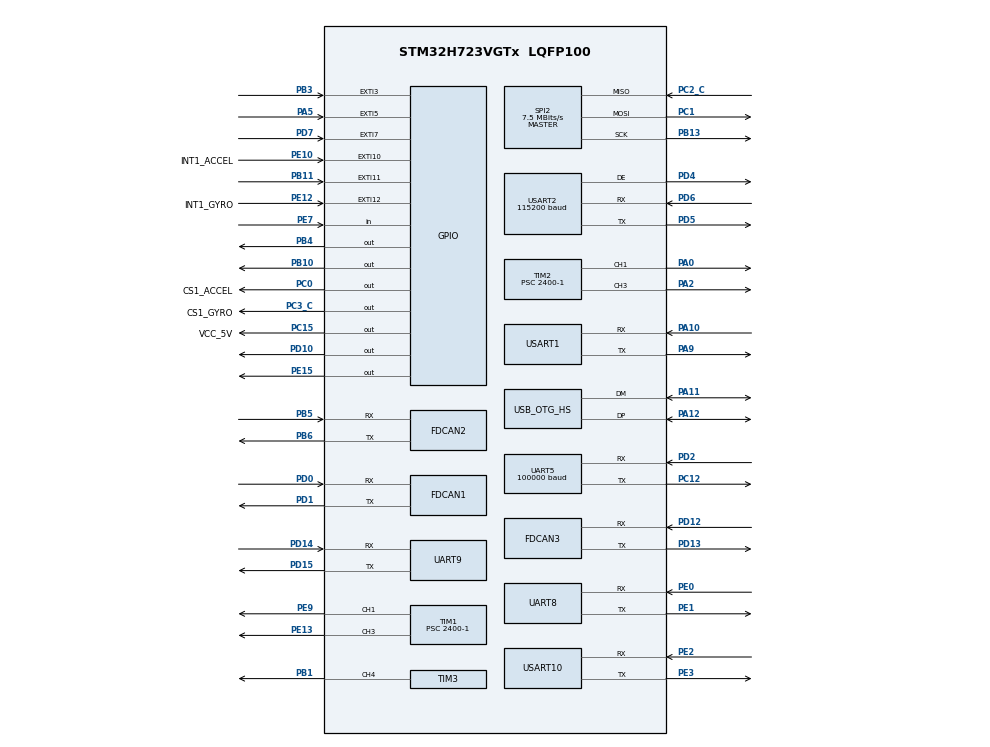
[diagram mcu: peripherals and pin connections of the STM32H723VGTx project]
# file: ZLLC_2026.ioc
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CORTEX_M7.CPU_DCache=Disabled
CORTEX_M7.CPU_ICache=Disabled
CORTEX_M7.MPU_Control=__NULL
CORTEX_M7.default_mode_Activation=0
Dma.Request0=UART5_RX
Dma.Request1=SPI2_RX
Dma.Request10=USART2_TX
Dma.Request2=SPI2_TX
Dma.Request3=USART10_RX
Dma.Request4=USART1_RX
Dma.Request5=UART8_RX
Dma.Request6=UART8_TX
Dma.Request7=UART9_RX
Dma.Request8=UART9_TX
Dma.Request9=USART2_RX
Dma.SPI2_RX.1.Direction=DMA_PERIPH_TO_MEMORY
Dma.SPI2_RX.1.EventEnable=DISABLE
Dma.SPI2_RX.1.FIFOMode=DMA_FIFOMODE_DISABLE
Dma.SPI2_RX.1.Instance=DMA1_Stream2
Dma.SPI2_RX.1.MemDataAlignment=DMA_MDATAALIGN_BYTE
Dma.SPI2_RX.1.MemInc=DMA_MINC_ENABLE
Dma.SPI2_RX.1.Mode=DMA_NORMAL
Dma.SPI2_RX.1.PeriphDataAlignment=DMA_PDATAALIGN_BYTE
Dma.SPI2_RX.1.PeriphInc=DMA_PINC_DISABLE
Dma.SPI2_RX.1.Polarity=HAL_DMAMUX_REQ_GEN_RISING
Dma.SPI2_RX.1.Priority=DMA_PRIORITY_VERY_HIGH
Dma.SPI2_RX.1.RequestNumber=1
Dma.SPI2_RX.1.SignalID=NONE
Dma.SPI2_RX.1.SyncEnable=DISABLE
Dma.SPI2_RX.1.SyncPolarity=HAL_DMAMUX_SYNC_NO_EVENT
Dma.SPI2_RX.1.SyncRequestNumber=1
Dma.SPI2_RX.1.SyncSignalID=NONE
Dma.SPI2_TX.2.Direction=DMA_MEMORY_TO_PERIPH
Dma.SPI2_TX.2.EventEnable=DISABLE
Dma.SPI2_TX.2.FIFOMode=DMA_FIFOMODE_DISABLE
Dma.SPI2_TX.2.Instance=DMA1_Stream1
Dma.SPI2_TX.2.MemDataAlignment=DMA_MDATAALIGN_BYTE
Dma.SPI2_TX.2.MemInc=DMA_MINC_ENABLE
Dma.SPI2_TX.2.Mode=DMA_NORMAL
Dma.SPI2_TX.2.PeriphDataAlignment=DMA_PDATAALIGN_BYTE
Dma.SPI2_TX.2.PeriphInc=DMA_PINC_DISABLE
Dma.SPI2_TX.2.Polarity=HAL_DMAMUX_REQ_GEN_RISING
Dma.SPI2_TX.2.Priority=DMA_PRIORITY_HIGH
Dma.SPI2_TX.2.RequestNumber=1
Dma.SPI2_TX.2.SignalID=NONE
Dma.SPI2_TX.2.SyncEnable=DISABLE
Dma.SPI2_TX.2.SyncPolarity=HAL_DMAMUX_SYNC_NO_EVENT
Dma.SPI2_TX.2.SyncRequestNumber=1
Dma.SPI2_TX.2.SyncSignalID=NONE
Dma.UART5_RX.0.Direction=DMA_PERIPH_TO_MEMORY
Dma.UART5_RX.0.EventEnable=DISABLE
Dma.UART5_RX.0.FIFOMode=DMA_FIFOMODE_DISABLE
Dma.UART5_RX.0.Instance=DMA1_Stream0
Dma.UART5_RX.0.MemDataAlignment=DMA_MDATAALIGN_BYTE
Dma.UART5_RX.0.MemInc=DMA_MINC_ENABLE
Dma.UART5_RX.0.Mode=DMA_NORMAL
Dma.UART5_RX.0.PeriphDataAlignment=DMA_PDATAALIGN_BYTE
Dma.UART5_RX.0.PeriphInc=DMA_PINC_DISABLE
Dma.UART5_RX.0.Polarity=HAL_DMAMUX_REQ_GEN_RISING
Dma.UART5_RX.0.Priority=DMA_PRIORITY_VERY_HIGH
Dma.UART5_RX.0.RequestNumber=1
Dma.UART5_RX.0.SignalID=NONE
Dma.UART5_RX.0.SyncEnable=DISABLE
Dma.UART5_RX.0.SyncPolarity=HAL_DMAMUX_SYNC_NO_EVENT
Dma.UART5_RX.0.SyncRequestNumber=1
Dma.UART5_RX.0.SyncSignalID=NONE
Dma.UART8_RX.5.Direction=DMA_PERIPH_TO_MEMORY
Dma.UART8_RX.5.EventEnable=DISABLE
Dma.UART8_RX.5.FIFOMode=DMA_FIFOMODE_DISABLE
Dma.UART8_RX.5.Instance=DMA1_Stream6
Dma.UART8_RX.5.MemDataAlignment=DMA_MDATAALIGN_BYTE
Dma.UART8_RX.5.MemInc=DMA_MINC_ENABLE
Dma.UART8_RX.5.Mode=DMA_CIRCULAR
Dma.UART8_RX.5.PeriphDataAlignment=DMA_PDATAALIGN_BYTE
Dma.UART8_RX.5.PeriphInc=DMA_PINC_DISABLE
Dma.UART8_RX.5.Polarity=HAL_DMAMUX_REQ_GEN_RISING
Dma.UART8_RX.5.Priority=DMA_PRIORITY_LOW
Dma.UART8_RX.5.RequestNumber=1
Dma.UART8_RX.5.SignalID=NONE
Dma.UART8_RX.5.SyncEnable=DISABLE
Dma.UART8_RX.5.SyncPolarity=HAL_DMAMUX_SYNC_NO_EVENT
Dma.UART8_RX.5.SyncRequestNumber=1
Dma.UART8_RX.5.SyncSignalID=NONE
Dma.UART8_TX.6.Direction=DMA_MEMORY_TO_PERIPH
Dma.UART8_TX.6.EventEnable=DISABLE
Dma.UART8_TX.6.FIFOMode=DMA_FIFOMODE_DISABLE
Dma.UART8_TX.6.Instance=DMA1_Stream7
Dma.UART8_TX.6.MemDataAlignment=DMA_MDATAALIGN_BYTE
Dma.UART8_TX.6.MemInc=DMA_MINC_ENABLE
Dma.UART8_TX.6.Mode=DMA_NORMAL
Dma.UART8_TX.6.PeriphDataAlignment=DMA_PDATAALIGN_BYTE
Dma.UART8_TX.6.PeriphInc=DMA_PINC_DISABLE
Dma.UART8_TX.6.Polarity=HAL_DMAMUX_REQ_GEN_RISING
Dma.UART8_TX.6.Priority=DMA_PRIORITY_LOW
Dma.UART8_TX.6.RequestNumber=1
Dma.UART8_TX.6.SignalID=NONE
Dma.UART8_TX.6.SyncEnable=DISABLE
Dma.UART8_TX.6.SyncPolarity=HAL_DMAMUX_SYNC_NO_EVENT
Dma.UART8_TX.6.SyncRequestNumber=1
Dma.UART8_TX.6.SyncSignalID=NONE
Dma.UART9_RX.7.Direction=DMA_PERIPH_TO_MEMORY
Dma.UART9_RX.7.EventEnable=DISABLE
Dma.UART9_RX.7.FIFOMode=DMA_FIFOMODE_DISABLE
Dma.UART9_RX.7.Instance=DMA2_Stream0
Dma.UART9_RX.7.MemDataAlignment=DMA_MDATAALIGN_BYTE
Dma.UART9_RX.7.MemInc=DMA_MINC_ENABLE
Dma.UART9_RX.7.Mode=DMA_CIRCULAR
Dma.UART9_RX.7.PeriphDataAlignment=DMA_PDATAALIGN_BYTE
Dma.UART9_RX.7.PeriphInc=DMA_PINC_DISABLE
Dma.UART9_RX.7.Polarity=HAL_DMAMUX_REQ_GEN_RISING
Dma.UART9_RX.7.Priority=DMA_PRIORITY_LOW
Dma.UART9_RX.7.RequestNumber=1
Dma.UART9_RX.7.SignalID=NONE
Dma.UART9_RX.7.SyncEnable=DISABLE
Dma.UART9_RX.7.SyncPolarity=HAL_DMAMUX_SYNC_NO_EVENT
Dma.UART9_RX.7.SyncRequestNumber=1
Dma.UART9_RX.7.SyncSignalID=NONE
Dma.UART9_TX.8.Direction=DMA_MEMORY_TO_PERIPH
Dma.UART9_TX.8.EventEnable=DISABLE
Dma.UART9_TX.8.FIFOMode=DMA_FIFOMODE_DISABLE
Dma.UART9_TX.8.Instance=DMA2_Stream1
Dma.UART9_TX.8.MemDataAlignment=DMA_MDATAALIGN_BYTE
Dma.UART9_TX.8.MemInc=DMA_MINC_ENABLE
Dma.UART9_TX.8.Mode=DMA_NORMAL
Dma.UART9_TX.8.PeriphDataAlignment=DMA_PDATAALIGN_BYTE
Dma.UART9_TX.8.PeriphInc=DMA_PINC_DISABLE
Dma.UART9_TX.8.Polarity=HAL_DMAMUX_REQ_GEN_RISING
Dma.UART9_TX.8.Priority=DMA_PRIORITY_LOW
Dma.UART9_TX.8.RequestNumber=1
Dma.UART9_TX.8.SignalID=NONE
Dma.UART9_TX.8.SyncEnable=DISABLE
Dma.UART9_TX.8.SyncPolarity=HAL_DMAMUX_SYNC_NO_EVENT
Dma.UART9_TX.8.SyncRequestNumber=1
Dma.UART9_TX.8.SyncSignalID=NONE
Dma.USART10_RX.3.Direction=DMA_PERIPH_TO_MEMORY
Dma.USART10_RX.3.EventEnable=DISABLE
Dma.USART10_RX.3.FIFOMode=DMA_FIFOMODE_ENABLE
Dma.USART10_RX.3.FIFOThreshold=DMA_FIFO_THRESHOLD_FULL
Dma.USART10_RX.3.Instance=DMA1_Stream3
Dma.USART10_RX.3.MemBurst=DMA_MBURST_SINGLE
Dma.USART10_RX.3.MemDataAlignment=DMA_MDATAALIGN_BYTE
Dma.USART10_RX.3.MemInc=DMA_MINC_ENABLE
Dma.USART10_RX.3.Mode=DMA_CIRCULAR
Dma.USART10_RX.3.PeriphBurst=DMA_PBURST_SINGLE
Dma.USART10_RX.3.PeriphDataAlignment=DMA_PDATAALIGN_BYTE
Dma.USART10_RX.3.PeriphInc=DMA_PINC_DISABLE
Dma.USART10_RX.3.Polarity=HAL_DMAMUX_REQ_GEN_RISING
Dma.USART10_RX.3.Priority=DMA_PRIORITY_LOW
Dma.USART10_RX.3.RequestNumber=1
Dma.USART10_RX.3.SignalID=NONE
Dma.USART10_RX.3.SyncEnable=DISABLE
Dma.USART10_RX.3.SyncPolarity=HAL_DMAMUX_SYNC_NO_EVENT
Dma.USART10_RX.3.SyncRequestNumber=1
Dma.USART10_RX.3.SyncSignalID=NONE
Dma.USART1_RX.4.Direction=DMA_PERIPH_TO_MEMORY
Dma.USART1_RX.4.EventEnable=DISABLE
Dma.USART1_RX.4.FIFOMode=DMA_FIFOMODE_DISABLE
Dma.USART1_RX.4.Instance=DMA1_Stream4
Dma.USART1_RX.4.MemDataAlignment=DMA_MDATAALIGN_BYTE
Dma.USART1_RX.4.MemInc=DMA_MINC_ENABLE
Dma.USART1_RX.4.Mode=DMA_CIRCULAR
Dma.USART1_RX.4.PeriphDataAlignment=DMA_PDATAALIGN_BYTE
Dma.USART1_RX.4.PeriphInc=DMA_PINC_DISABLE
Dma.USART1_RX.4.Polarity=HAL_DMAMUX_REQ_GEN_RISING
Dma.USART1_RX.4.Priority=DMA_PRIORITY_LOW
Dma.USART1_RX.4.RequestNumber=1
Dma.USART1_RX.4.SignalID=NONE
Dma.USART1_RX.4.SyncEnable=DISABLE
Dma.USART1_RX.4.SyncPolarity=HAL_DMAMUX_SYNC_NO_EVENT
Dma.USART1_RX.4.SyncRequestNumber=1
Dma.USART1_RX.4.SyncSignalID=NONE
Dma.USART2_RX.9.Direction=DMA_PERIPH_TO_MEMORY
Dma.USART2_RX.9.EventEnable=DISABLE
Dma.USART2_RX.9.FIFOMode=DMA_FIFOMODE_DISABLE
Dma.USART2_RX.9.Instance=DMA2_Stream2
Dma.USART2_RX.9.MemDataAlignment=DMA_MDATAALIGN_BYTE
Dma.USART2_RX.9.MemInc=DMA_MINC_ENABLE
Dma.USART2_RX.9.Mode=DMA_CIRCULAR
Dma.USART2_RX.9.PeriphDataAlignment=DMA_PDATAALIGN_BYTE
Dma.USART2_RX.9.PeriphInc=DMA_PINC_DISABLE
Dma.USART2_RX.9.Polarity=HAL_DMAMUX_REQ_GEN_RISING
Dma.USART2_RX.9.Priority=DMA_PRIORITY_MEDIUM
Dma.USART2_RX.9.RequestNumber=1
Dma.USART2_RX.9.SignalID=NONE
Dma.USART2_RX.9.SyncEnable=DISABLE
Dma.USART2_RX.9.SyncPolarity=HAL_DMAMUX_SYNC_NO_EVENT
Dma.USART2_RX.9.SyncRequestNumber=1
Dma.USART2_RX.9.SyncSignalID=NONE
Dma.USART2_TX.10.Direction=DMA_MEMORY_TO_PERIPH
Dma.USART2_TX.10.EventEnable=DISABLE
Dma.USART2_TX.10.FIFOMode=DMA_FIFOMODE_DISABLE
Dma.USART2_TX.10.Instance=DMA2_Stream3
Dma.USART2_TX.10.MemDataAlignment=DMA_MDATAALIGN_BYTE
Dma.USART2_TX.10.MemInc=DMA_MINC_ENABLE
Dma.USART2_TX.10.Mode=DMA_NORMAL
Dma.USART2_TX.10.PeriphDataAlignment=DMA_PDATAALIGN_BYTE
Dma.USART2_TX.10.PeriphInc=DMA_PINC_DISABLE
Dma.USART2_TX.10.Polarity=HAL_DMAMUX_REQ_GEN_RISING
Dma.USART2_TX.10.Priority=DMA_PRIORITY_MEDIUM
Dma.USART2_TX.10.RequestNumber=1
Dma.USART2_TX.10.SignalID=NONE
Dma.USART2_TX.10.SyncEnable=DISABLE
Dma.USART2_TX.10.SyncPolarity=HAL_DMAMUX_SYNC_NO_EVENT
Dma.USART2_TX.10.SyncRequestNumber=1
Dma.USART2_TX.10.SyncSignalID=NONE
FDCAN1.AutoRetransmission=DISABLE
FDCAN1.CalculateBaudRateNominal=1000000
FDCAN1.CalculateTimeBitNominal=1000
FDCAN1.CalculateTimeQuantumNominal=25.0
FDCAN1.DataPrescaler=3
FDCAN1.DataSyncJumpWidth=10
FDCAN1.DataTimeSeg1=29
FDCAN1.DataTimeSeg2=10
FDCAN1.ExtFiltersNbr=0
FDCAN1.MessageRAMOffset=0
FDCAN1.NominalPrescaler=3
FDCAN1.NominalSyncJumpWidth=10
FDCAN1.NominalTimeSeg1=29
FDCAN1.NominalTimeSeg2=10
FDCAN1.ProtocolException=ENABLE
FDCAN1.RxBuffersNbr=0
FDCAN1.RxFifo0ElmtSize=FDCAN_DATA_BYTES_8
FDCAN1.RxFifo0ElmtsNbr=12
FDCAN1.RxFifo1ElmtSize=FDCAN_DATA_BYTES_8
FDCAN1.StdFiltersNbr=1
FDCAN1.TxBuffersNbr=0
FDCAN1.TxEventsNbr=0
FDCAN1.TxFifoQueueElmtsNbr=12
FDCAN2.CalculateBaudRateNominal=1000000
FDCAN2.CalculateTimeBitNominal=1000
FDCAN2.CalculateTimeQuantumNominal=25.0
FDCAN2.DataPrescaler=3
FDCAN2.DataSyncJumpWidth=10
FDCAN2.DataTimeSeg1=29
FDCAN2.DataTimeSeg2=10
FDCAN2.ExtFiltersNbr=0
FDCAN2.MessageRAMOffset=854
FDCAN2.NominalPrescaler=3
FDCAN2.NominalSyncJumpWidth=10
FDCAN2.NominalTimeSeg1=29
FDCAN2.NominalTimeSeg2=10
FDCAN2.ProtocolException=ENABLE
FDCAN2.RxFifo0ElmtsNbr=0
FDCAN2.RxFifo1ElmtsNbr=12
FDCAN2.StdFiltersNbr=1
FDCAN2.TxFifoQueueElmtsNbr=12
FDCAN3.CalculateBaudRateNominal=1000000
FDCAN3.CalculateTimeBitNominal=1000
FDCAN3.CalculateTimeQuantumNominal=25.0
FDCAN3.DataPrescaler=3
FDCAN3.DataSyncJumpWidth=10
FDCAN3.DataTimeSeg1=29
FDCAN3.DataTimeSeg2=10
FDCAN3.ExtFiltersNbr=0
FDCAN3.MessageRAMOffset=1707
FDCAN3.NominalPrescaler=3
FDCAN3.NominalSyncJumpWidth=10
FDCAN3.NominalTimeSeg1=29
FDCAN3.NominalTimeSeg2=10
FDCAN3.ProtocolException=ENABLE
FDCAN3.RxFifo0ElmtsNbr=12
FDCAN3.RxFifo1ElmtsNbr=0
FDCAN3.StdFiltersNbr=1
FDCAN3.TxFifoQueueElmtsNbr=12
IWDG1.Prescaler=IWDG_PRESCALER_64
IWDG1.Reload=125
Mcu.Family=STM32H7
Mcu.Name=STM32H723VGTx
Mcu.Package=LQFP100
NVIC.DMA1_Stream0_IRQn=true\:0\:0\:true\:false\:true\:false\:true\:true
NVIC.DMA1_Stream1_IRQn=true\:0\:0\:true\:false\:true\:false\:true\:true
NVIC.DMA1_Stream2_IRQn=true\:0\:0\:true\:false\:true\:false\:true\:true
NVIC.DMA1_Stream3_IRQn=true\:0\:0\:true\:false\:true\:false\:true\:true
NVIC.DMA1_Stream4_IRQn=true\:1\:0\:true\:false\:true\:false\:true\:true
NVIC.DMA1_Stream6_IRQn=true\:0\:0\:false\:false\:true\:false\:true\:true
NVIC.DMA1_Stream7_IRQn=true\:0\:0\:false\:false\:true\:false\:true\:true
NVIC.DMA2_Stream0_IRQn=true\:0\:0\:false\:false\:true\:false\:true\:true
NVIC.DMA2_Stream1_IRQn=true\:0\:0\:false\:false\:true\:false\:true\:true
NVIC.DMA2_Stream2_IRQn=true\:0\:0\:false\:false\:true\:false\:true\:true
NVIC.DMA2_Stream3_IRQn=true\:0\:0\:false\:false\:true\:false\:true\:true
NVIC.EXTI15_10_IRQn=true\:0\:0\:true\:false\:true\:true\:true\:true
NVIC.EXTI3_IRQn=true\:0\:0\:false\:false\:true\:true\:true\:true
NVIC.EXTI9_5_IRQn=true\:0\:0\:false\:false\:true\:true\:true\:true
NVIC.FDCAN1_IT0_IRQn=true\:1\:0\:true\:false\:true\:true\:true\:true
NVIC.FDCAN2_IT0_IRQn=true\:1\:0\:true\:false\:true\:true\:true\:true
NVIC.FDCAN2_IT1_IRQn=true\:0\:0\:false\:false\:true\:true\:true\:true
NVIC.FDCAN3_IT0_IRQn=true\:3\:0\:true\:false\:true\:true\:true\:true
NVIC.OTG_HS_IRQn=true\:0\:0\:true\:false\:true\:true\:true\:true
NVIC.PriorityGroup=NVIC_PRIORITYGROUP_3
NVIC.SPI2_IRQn=true\:0\:0\:true\:false\:true\:true\:true\:true
NVIC.TIM5_IRQn=true\:1\:0\:true\:false\:true\:true\:true\:true
NVIC.UART5_IRQn=true\:6\:0\:true\:false\:true\:true\:true\:true
NVIC.UART8_IRQn=true\:6\:0\:true\:false\:true\:true\:true\:true
NVIC.UART9_IRQn=true\:6\:0\:true\:false\:true\:true\:true\:true
NVIC.USART10_IRQn=true\:6\:0\:true\:false\:true\:true\:true\:true
NVIC.USART1_IRQn=true\:1\:0\:true\:false\:true\:true\:true\:true
NVIC.USART2_IRQn=true\:3\:0\:true\:false\:true\:true\:true\:true
PA0.Signal=S_TIM2_CH1_ETR
PA10.Mode=Asynchronous
PA10.Signal=USART1_RX
PA11.Mode=Device_Only_FS
PA11.Signal=USB_OTG_HS_DM
PA12.Mode=Device_Only_FS
PA12.Signal=USB_OTG_HS_DP
PA13(JTMS/SWDIO).Mode=Serial_Wire
PA13(JTMS/SWDIO).Signal=DEBUG_JTMS-SWDIO
PA14(JTCK/SWCLK).Mode=Serial_Wire
PA14(JTCK/SWCLK).Signal=DEBUG_JTCK-SWCLK
PA2.Signal=S_TIM2_CH3
PA5.GPIO_PuPd=GPIO_PULLDOWN
PA5.Signal=GPXTI5
PA9.Mode=Asynchronous
PA9.Signal=USART1_TX
PB1.Signal=S_TIM3_CH4
PB10.GPIO_PuPd=GPIO_PULLUP
PB10.PinState=GPIO_PIN_SET
PB10.Signal=GPIO_Output
PB11.GPIO_PuPd=GPIO_PULLDOWN
PB11.Signal=GPXTI11
PB13.GPIO_Speed=GPIO_SPEED_FREQ_VERY_HIGH
PB13.Mode=Full_Duplex_Master
PB13.Signal=SPI2_SCK
PB3(JTDO/TRACESWO).GPIO_ModeDefaultEXTI=GPIO_MODE_IT_RISING
PB3(JTDO/TRACESWO).GPIO_PuPd=GPIO_PULLDOWN
PB3(JTDO/TRACESWO).Signal=GPXTI3
PB4(NJTRST).GPIO_PuPd=GPIO_PULLUP
PB4(NJTRST).PinState=GPIO_PIN_SET
PB4(NJTRST).Signal=GPIO_Output
PB5.Mode=FDCAN_Activate
PB5.Signal=FDCAN2_RX
PB6.Mode=FDCAN_Activate
PB6.Signal=FDCAN2_TX
PC0.GPIO_Label=CS1_ACCEL
PC0.GPIO_PuPd=GPIO_PULLUP
PC0.GPIO_Speed=GPIO_SPEED_FREQ_HIGH
PC0.PinState=GPIO_PIN_SET
PC0.Signal=GPIO_Output
PC1.GPIO_Speed=GPIO_SPEED_FREQ_VERY_HIGH
PC1.Mode=Full_Duplex_Master
PC1.Signal=SPI2_MOSI
PC12.Mode=Asynchronous
PC12.Signal=UART5_TX
PC15-OSC32_OUT.GPIO_Label=VCC_5V
PC15-OSC32_OUT.PinState=GPIO_PIN_SET
PC15-OSC32_OUT.Signal=GPIO_Output
PC2_C.GPIO_Speed=GPIO_SPEED_FREQ_VERY_HIGH
PC2_C.Mode=Full_Duplex_Master
PC2_C.Signal=SPI2_MISO
PC3_C.GPIO_Label=CS1_GYRO
PC3_C.GPIO_PuPd=GPIO_PULLUP
PC3_C.GPIO_Speed=GPIO_SPEED_FREQ_HIGH
PC3_C.PinState=GPIO_PIN_SET
PC3_C.Signal=GPIO_Output
PD0.Mode=FDCAN_Activate
PD0.Signal=FDCAN1_RX
PD1.Mode=FDCAN_Activate
PD1.Signal=FDCAN1_TX
PD10.GPIO_PuPd=GPIO_PULLUP
PD10.PinState=GPIO_PIN_SET
PD10.Signal=GPIO_Output
PD12.Mode=FDCAN_Activate
PD12.Signal=FDCAN3_RX
PD13.Mode=FDCAN_Activate
PD13.Signal=FDCAN3_TX
PD14.Mode=Asynchronous
PD14.Signal=UART9_RX
PD15.Mode=Asynchronous
PD15.Signal=UART9_TX
PD2.Mode=Asynchronous
PD2.Signal=UART5_RX
PD4.Mode=Hardware Flow Control (RS485)
PD4.Signal=USART2_DE
PD5.Mode=Asynchronous
PD5.Signal=USART2_TX
PD6.Mode=Asynchronous
PD6.Signal=USART2_RX
PD7.GPIO_PuPd=GPIO_PULLDOWN
PD7.Signal=GPXTI7
PE0.Mode=Asynchronous
PE0.Signal=UART8_RX
PE1.Mode=Asynchronous
PE1.Signal=UART8_TX
PE10.GPIO_Label=INT1_ACCEL
PE10.GPIO_ModeDefaultEXTI=GPIO_MODE_IT_FALLING
PE10.GPIO_PuPd=GPIO_PULLUP
PE10.Signal=GPXTI10
PE12.GPIO_Label=INT1_GYRO
PE12.GPIO_ModeDefaultEXTI=GPIO_MODE_IT_FALLING
PE12.GPIO_PuPd=GPIO_PULLUP
PE12.Signal=GPXTI12
PE13.Signal=S_TIM1_CH3
PE15.GPIO_PuPd=GPIO_PULLUP
PE15.PinState=GPIO_PIN_SET
PE15.Signal=GPIO_Output
PE2.Mode=Asynchronous
PE2.Signal=USART10_RX
PE3.Mode=Asynchronous
PE3.Signal=USART10_TX
PE7.GPIO_PuPd=GPIO_PULLUP
PE7.Signal=GPIO_Input
PE9.Signal=S_TIM1_CH1
PH0-OSC_IN.Mode=HSE-External-Oscillator
PH0-OSC_IN.Signal=RCC_OSC_IN
PH1-OSC_OUT.Mode=HSE-External-Oscillator
PH1-OSC_OUT.Signal=RCC_OSC_OUT
ProjectManager.HeapSize=0x6000
ProjectManager.StackSize=0x8000
ProjectManager.TargetToolchain=MDK-ARM V5.32
RCC.ADCFreq_Value=150000000
RCC.APB1Freq_Value=120000000
RCC.APB2Freq_Value=120000000
RCC.APB3Freq_Value=120000000
RCC.APB4Freq_Value=120000000
RCC.CortexFreq_Value=480000000
RCC.D1PPRE=RCC_APB3_DIV2
RCC.D2PPRE1=RCC_APB1_DIV2
RCC.D2PPRE2=RCC_APB2_DIV2
RCC.D3PPRE=RCC_APB4_DIV2
RCC.DIVM1=2
RCC.DIVM2=2
RCC.DIVN1=40
RCC.DIVN2=25
RCC.DIVP1=1
RCC.DIVQ1=4
RCC.DIVQ2=3
RCC.HCLKFreq_Value=240000000
RCC.HPRE=RCC_HCLK_DIV2
RCC.HSE_VALUE=24000000
RCC.PLL2FRACN=0
RCC.PLLFRACN=0
RCC.PLLSourceVirtual=RCC_PLLSOURCE_HSE
RCC.SYSCLKFreq_VALUE=480000000
RCC.SYSCLKSource=RCC_SYSCLKSOURCE_PLLCLK
RCC.USBCLockSelection=RCC_USBCLKSOURCE_HSI48
RCC.USBFreq_Value=48000000
SH.S_TIM1_CH1.0=TIM1_CH1,PWM Generation1 CH1
SH.S_TIM1_CH3.0=TIM1_CH3,PWM Generation3 CH3
SH.S_TIM2_CH1_ETR.0=TIM2_CH1,PWM Generation1 CH1
SH.S_TIM2_CH3.0=TIM2_CH3,PWM Generation3 CH3
SH.S_TIM3_CH4.0=TIM3_CH4,PWM Generation4 CH4
SPI2.BaudRatePrescaler=SPI_BAUDRATEPRESCALER_16
SPI2.CLKPhase=SPI_PHASE_2EDGE
SPI2.CLKPolarity=SPI_POLARITY_HIGH
SPI2.CalculateBaudRate=7.5 MBits/s
SPI2.DataSize=SPI_DATASIZE_8BIT
SPI2.Direction=SPI_DIRECTION_2LINES
SPI2.Mode=SPI_MODE_MASTER
SPI2.VirtualType=VM_MASTER
TIM1.Channel-PWM\ Generation1\ CH1=TIM_CHANNEL_1
TIM1.Channel-PWM\ Generation3\ CH3=TIM_CHANNEL_3
TIM1.Period=2000-1
TIM1.Prescaler=2400-1
TIM2.Channel-PWM\ Generation1\ CH1=TIM_CHANNEL_1
TIM2.Channel-PWM\ Generation3\ CH3=TIM_CHANNEL_3
TIM2.Period=2000-1
TIM2.Prescaler=2400-1
TIM3.AutoReloadPreload=TIM_AUTORELOAD_PRELOAD_ENABLE
TIM3.Channel-PWM\ Generation4\ CH4=TIM_CHANNEL_4
TIM3.Period=10000-1
TIM3.Prescaler=24-1
TIM5.Period=1000-1
TIM5.Prescaler=240-1
UART5.BaudRate=100000
UART5.Mode=MODE_TX_RX
UART5.Parity=PARITY_EVEN
UART5.StopBits=UART_STOPBITS_2
UART5.WordLength=WORDLENGTH_9B
USART1.VirtualMode-Asynchronous=VM_ASYNC
USART10.OverrunDisableParam=ADVFEATURE_OVERRUN_DISABLE
USART10.VirtualMode=VM_ASYNC
USART2.BaudRate=115200
USART2.VirtualMode-Asynchronous=VM_ASYNC
USART2.VirtualMode-Hardware\ Flow\ Control\ (RS485)=VM_ASYNC
USB_DEVICE.CLASS_NAME_HS=CDC
USB_DEVICE.VirtualMode=Cdc
USB_DEVICE.VirtualModeHS=Cdc_HS
USB_OTG_HS.VirtualMode-Device_Only_FS=Device_Only_FS
VP_IWDG1_VS_IWDG.Mode=IWDG_Activate
VP_MEMORYMAP_VS_MEMORYMAP.Mode=CurAppReg
VP_TIM1_VS_ClockSourceINT.Mode=Internal
VP_TIM2_VS_ClockSourceINT.Mode=Internal
VP_TIM3_VS_ClockSourceINT.Mode=Internal
VP_TIM5_VS_ClockSourceINT.Mode=Internal
VP_USB_DEVICE_VS_USB_DEVICE_CDC_HS.Mode=CDC_HS
board=custom

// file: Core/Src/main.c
/* USER CODE BEGIN Header */
/**
  ******************************************************************************
  * @file           : main.c
  * @brief          : Main program body
  ******************************************************************************
  * @attention
  *
  * Copyright (c) 2024 STMicroelectronics.
  * All rights reserved.
  *
  * This software is licensed under terms that can be found in the LICENSE file
  * in the root directory of this software component.
  * If no LICENSE file comes with this software, it is provided AS-IS.
  *
  ******************************************************************************
  */
/* USER CODE END Header */
#include "main.h"
#include "dma.h"
#include "fdcan.h"
#include "iwdg.h"
#include "memorymap.h"
#include "spi.h"
#include "tim.h"
#include "usart.h"
#include "usb_device.h"
#include "gpio.h"

/* USER CODE BEGIN Includes */
//#include "arm_math.h"
#include "tsk_config_and_callback.h"
#include "fault_handler.h"
/* USER CODE END Includes */

void SystemClock_Config(void);

int main(void)
{

  /* MCU Configuration--------------------------------------------------------*/

  /* Reset of all peripherals, Initializes the Flash interface and the Systick. */
  HAL_Init();

  /* USER CODE BEGIN Init */
  Fault_Enable();
  /* USER CODE END Init */

  /* Configure the system clock */
  SystemClock_Config();

  /* Initialize all configured peripherals */
  MX_GPIO_Init();
  MX_DMA_Init();
  MX_FDCAN1_Init();
  MX_FDCAN2_Init();
  MX_FDCAN3_Init();
  MX_SPI2_Init();
  MX_TIM3_Init();
  MX_USART1_UART_Init();
  MX_USART10_UART_Init();
  MX_USB_DEVICE_Init();
  MX_UART5_Init();
  MX_TIM5_Init();
  MX_UART8_Init();
  MX_UART9_Init();
  MX_IWDG1_Init();
  MX_TIM2_Init();
  MX_USART2_UART_Init();
  MX_TIM1_Init();
  /* USER CODE BEGIN 2 */

  Task_Init();

  /* USER CODE END 2 */

  /* Infinite loop */
  /* USER CODE BEGIN WHILE */
  while (1)
  {
    Task_Loop();
    /* USER CODE END WHILE */

  }
}

void SystemClock_Config(void)
{
  RCC_OscInitTypeDef RCC_OscInitStruct = {0};
  RCC_ClkInitTypeDef RCC_ClkInitStruct = {0};

  /** Supply configuration update enable
  */
  HAL_PWREx_ConfigSupply(PWR_LDO_SUPPLY);

  /** Configure the main internal regulator output voltage
  */
  __HAL_PWR_VOLTAGESCALING_CONFIG(PWR_REGULATOR_VOLTAGE_SCALE0);

  while(!__HAL_PWR_GET_FLAG(PWR_FLAG_VOSRDY)) {}

  /** Initializes the RCC Oscillators according to the specified parameters
  * in the RCC_OscInitTypeDef structure.
  */
  RCC_OscInitStruct.OscillatorType = RCC_OSCILLATORTYPE_HSI48|RCC_OSCILLATORTYPE_LSI
                              |RCC_OSCILLATORTYPE_HSE;
  RCC_OscInitStruct.HSEState = RCC_HSE_ON;
  RCC_OscInitStruct.LSIState = RCC_LSI_ON;
  RCC_OscInitStruct.HSI48State = RCC_HSI48_ON;
  RCC_OscInitStruct.PLL.PLLState = RCC_PLL_ON;
  RCC_OscInitStruct.PLL.PLLSource = RCC_PLLSOURCE_HSE;
  RCC_OscInitStruct.PLL.PLLM = 2;
  RCC_OscInitStruct.PLL.PLLN = 40;
  RCC_OscInitStruct.PLL.PLLP = 1;
  RCC_OscInitStruct.PLL.PLLQ = 4;
  RCC_OscInitStruct.PLL.PLLR = 2;
  RCC_OscInitStruct.PLL.PLLRGE = RCC_PLL1VCIRANGE_3;
  RCC_OscInitStruct.PLL.PLLVCOSEL = RCC_PLL1VCOWIDE;
  RCC_OscInitStruct.PLL.PLLFRACN = 0;
  if (HAL_RCC_OscConfig(&RCC_OscInitStruct) != HAL_OK)
  {
    Error_Handler();
  }

  /** Initializes the CPU, AHB and APB buses clocks
  */
  RCC_ClkInitStruct.ClockType = RCC_CLOCKTYPE_HCLK|RCC_CLOCKTYPE_SYSCLK
                              |RCC_CLOCKTYPE_PCLK1|RCC_CLOCKTYPE_PCLK2
                              |RCC_CLOCKTYPE_D3PCLK1|RCC_CLOCKTYPE_D1PCLK1;
  RCC_ClkInitStruct.SYSCLKSource = RCC_SYSCLKSOURCE_PLLCLK;
  RCC_ClkInitStruct.SYSCLKDivider = RCC_SYSCLK_DIV1;
  RCC_ClkInitStruct.AHBCLKDivider = RCC_HCLK_DIV2;
  RCC_ClkInitStruct.APB3CLKDivider = RCC_APB3_DIV2;
  RCC_ClkInitStruct.APB1CLKDivider = RCC_APB1_DIV2;
  RCC_ClkInitStruct.APB2CLKDivider = RCC_APB2_DIV2;
  RCC_ClkInitStruct.APB4CLKDivider = RCC_APB4_DIV2;

  if (HAL_RCC_ClockConfig(&RCC_ClkInitStruct, FLASH_LATENCY_3) != HAL_OK)
  {
    Error_Handler();
  }
}

void Error_Handler(void)
{
  __disable_irq();
  while (1)
  {
  }
}
